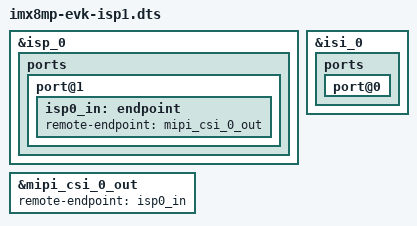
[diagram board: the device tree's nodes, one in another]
// SPDX-License-Identifier: (GPL-2.0+ OR MIT)
/*
 * Copyright 2022 Ideas on Board Oy
 */

/dts-v1/;
/plugin/;

/ {
	fragment@0 {
		target = <&isp_0>;
		__overlay__ {
			status = "okay";

			ports {
				port@1 {
					isp0_in: endpoint {
						remote-endpoint = <&mipi_csi_0_out>;
					};
				};
			};
		};
	};

	fragment@1 {
		target = <&mipi_csi_0_out>;
		__overlay__ {
			remote-endpoint = <&isp0_in>;
		};
	};

	fragment@2 {
		target = <&isi_0>;
		__overlay__ {
			ports {
				port@0 {
					/delete-node/ endpoint;
				};
			};
		};
	};
};
